# SN32F780 register map
Vendor: SONiX Technology Co., Ltd.; Series: SN32F780; File version: 0.75
CPU: CM0 r0p0, little endian, no MPU, no FPU, 2 interrupt priority bits
Registers are 32-bit, read-write, reset 0x0 unless marked. A register's access mark holds for its fields unless they carry their own. Offsets are from the block's base; [hi:lo] are bit positions; {n}, {i} and the like mark numbered series.

## SN_CT16B1 — 16-bit Timer 1 with Capture function
Base 0x40002000
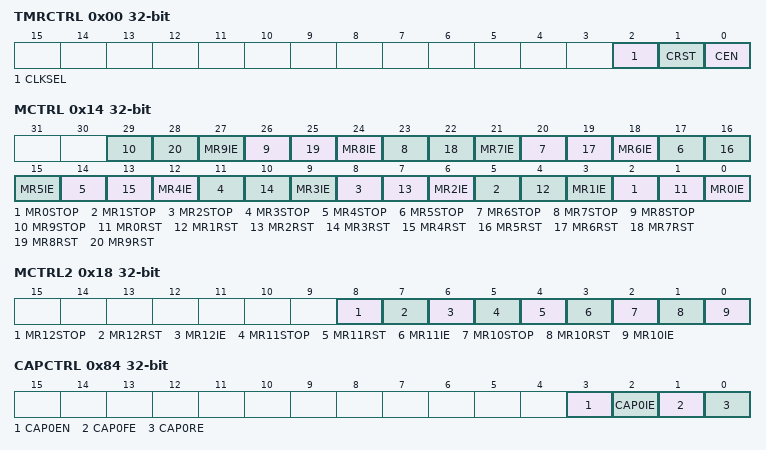
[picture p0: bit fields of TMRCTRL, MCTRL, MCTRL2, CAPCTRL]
0x00 TMRCTRL — Offset:0x00 CT16Bn Timer Control Register
  [2] CLKSEL — PCLK source
    0=HCLK (CT16Bn PCLK source=HCLK); 1=PLL_VCO (CT16Bn PCLK source=PLL_VCO)
  [1] CRST — Counter Reset
    0=Disable; 1=Reset Counter (Timer Counter and the Prescale Counter are synchronously reset on the next positive edge of PCLK)
  [0] CEN — Counter enable
    0=Disable counter; 1=Enable Timer Counter and Prescale Counter for counting
0x04 TC — Offset:0x04 CT16Bn Timer Counter Register
  [15:0] TC — Timer Counter
0x08 PRE — Offset:0x08 CT16Bn Prescale Register
  [7:0] PRE — Prescaler
0x0C PC — Offset:0x0C CT16Bn Prescale Counter Register
  [7:0] PC — Prescaler Counter
0x10 CNTCTRL — Offset:0x10 CT16Bn Counter Control Register
  [1:0] CTM — Counter/Timer Mode
    0=Timer Mode: every rising PCLK edge; 1=Counter Mode 1 (TC is incremented on rising edges on the CAP0 input selected by CIS bits.); 2=Counter Mode 2 (TC is incremented on falling edges on the CAP0 input selected by CIS bits.); 3=Counter Mode 3 (TC is incremented on both edges on the CAP0 input selected by CIS bits.)
0x14 MCTRL (reset mask 0x3FFFFFF) — Offset:0x14 CT16Bn Match Control Register
  [3n+2] MR{n}STOP (n=0..9) — Stop TC and PC and clear CEN bit when MR{n} matches TC
    0=Disable; 1=Enable (Stop TC and PC and clear CEN bit when MR{n} matches TC)
  [3n+1] MR{n}RST (n=0..9) — Enable reset TC when MR{n} matches TC
    0=Disable; 1=Enable (Reset TC when MR{n} matches TC)
  [3n] MR{n}IE (n=0..9) — Enable generating an interrupt when MR{n} matches TC
    0=Disable; 1=Enable (Generating an interrupt when MR{n} matches TC)
0x18 MCTRL2 — Offset:0x18 CT16Bn Match Control Register 2
  [8] MR12STOP — Stop TC and PC and clear CEN bit when MR12 matches TC
    0=Disable; 1=Enable (Stop TC and PC and clear CEN bit when MR12 matches TC)
  [7] MR12RST — Enable reset TC when MR12 matches TC
    0=Disable; 1=Enable (Reset TC when MR12 matches TC)
  [6] MR12IE — Enable generating an interrupt when MR12 matches TC
    0=Disable; 1=Enable (Generating an interrupt when MR12 matches TC)
  [5] MR11STOP — Stop TC and PC and clear CEN bit when MR11 matches TC
    0=Disable; 1=Enable (Stop TC and PC and clear CEN bit when MR11 matches TC)
  [4] MR11RST — Enable reset TC when MR11 matches TC
    0=Disable; 1=Enable (Reset TC when MR11 matches TC)
  [3] MR11IE — Enable generating an interrupt when MR11 matches TC
    0=Disable; 1=Enable (Generating an interrupt when MR11 matches TC)
  [2] MR10STOP — Stop TC and PC and clear CEN bit when MR10 matches TC
    0=Disable; 1=Enable (Stop TC and PC and clear CEN bit when MR10 matches TC)
  [1] MR10RST — Enable reset TC when MR10 matches TC
    0=Disable; 1=Enable (Reset TC when MR10 matches TC)
  [0] MR10IE — Enable generating an interrupt when MR10 matches TC
    0=Disable; 1=Enable (Generating an interrupt when MR10 matches TC)
{0x20+4i} MR{i} (reset mask 0xFFFF) (i=0..12) — Offset:{0x20+4i} CT16Bn MR{i} Register
0x84 CAPCTRL — Offset:0x84 CT16Bn Capture Control Register
  [3] CAP0EN — CAP0 function enable
    0=Disable; 1=Enable CAP0 function for external Capture pin
  [2] CAP0IE — Interrupt on CT16Bn_CAP0 event
    0=Disable; 1=Enable (A CAP0 load due to a CT16Bn_CAP0 event will generate an interrupt.)
  [1] CAP0FE — Capture/Reset on CT16Bn_CAP0 signal falling edge
    0=Disable; 1=Enable (A sequence of 1 then 0 on CT16Bn_CAP0 will cause CAP0 to be loaded with the contents of TC.)
  [0] CAP0RE — Capture/Reset on CT16Bn_CAP0 signal rising edge
    0=Disable; 1=Enable (A sequence of 0 then 1 on CT16Bn_CAP0 will cause CAP0 to be loaded with the contents of TC.)
0x88 CAP0 ro — Offset:0x88 CT16Bn CAP0 Register
  [15:0] CAP0 — Timer counter capture value
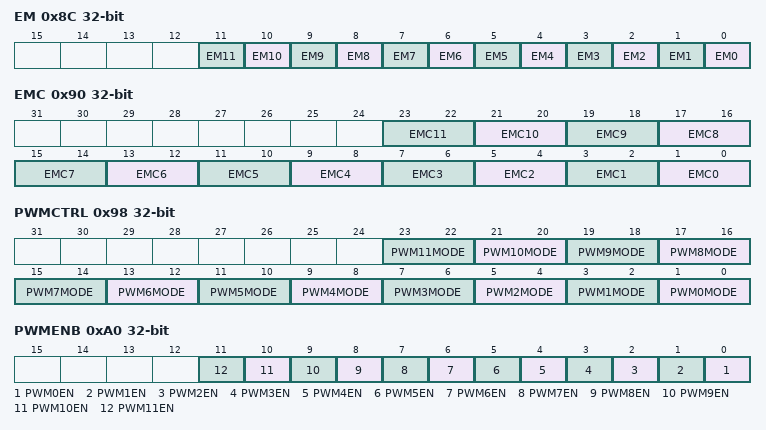
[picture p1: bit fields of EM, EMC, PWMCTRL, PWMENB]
0x8C EM — Offset:0x8C CT16Bn External Match Register
  [n] EM{n} (n=8..11) — When the TC matches MR{n}, this bit will act according to EMC{n}[1:0], and also drive the state of CT16Bn_PWM{n-8} output.
  [n] EM{n} (n=4..7) — When the TC matches MR{n}, this bit will act according to EMC{n}[1:0], and also drive the state of CT16Bn_PWM{n-4} output.
  [n] EM{n} (n=0..3) — When the TC matches MR{n}, this bit will act according to EMC{n}[1:0], and also drive the state of CT16Bn_PWM{n} output.
0x90 EMC — Offset:0x90 CT16Bn External Match Control register
  [2n+1:2n] EMC{n} (n=0..11) — CT16Bn_PWM{n} functionality
    0=Do Nothing; 1=Low (CT16Bn_PWM{n} pin is LOW); 2=High (CT16Bn_PWM{n} pin is HIGH); 3=Toggle CT16Bn_PWM{n} pin
0x98 PWMCTRL — Offset:0x98 CT16Bn PWM Control Register
  [2n+1:2n] PWM{n}MODE (n=0..11) — PWM{n} output mode
    0=PWM mode 1 (During up-counting, PWM{n} is 0 when TC is less than MR{n}. During down-counting, PWM{n} is 1 when TC is larger/equal than MR{n}); 1=PWM mode 2 (During up-counting, PWM{n} is 1 when TC is less than MR{n}. During down-counting, PWM{n} is 0 when TC is larger/equal than MR{n}); 2=Force 0 (PWM{n} is forced to 0); 3=Force 1 (PWM{n} is forced to 1)
0xA0 PWMENB — Offset:0xA0 CT16Bn PWM Enable register
  [n] PWM{n}EN (n=0..11) — PWM{n} enable
    0=Disable (CT16Bn_PWM{n} is controlled by EM{n}); 1=Enable PWM mode for CT16Bn_PWM{n}
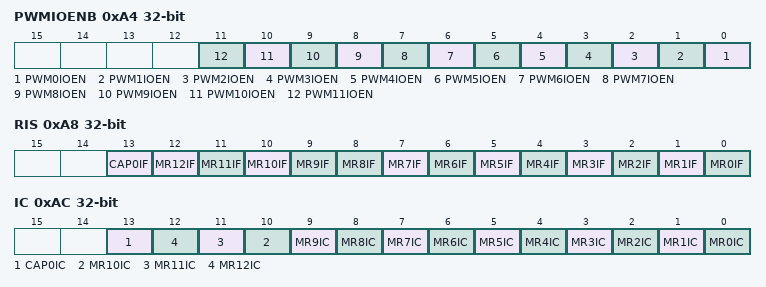
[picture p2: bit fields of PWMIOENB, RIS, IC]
0xA4 PWMIOENB — Offset:0xA4 CT16Bn PWM IO Enable register
  [n] PWM{n}IOEN (n=0..11) — CT16Bn_PWM{n}/GPIO selection
    0=Disable (CT16Bn_PWM{n} pin is act as GPIO); 1=Enable (CT16Bn_PWM{n} pin act as match output, and output depends on PWM{n}EN bit)
0xA8 RIS ro — Offset:0xA8 CT16Bn Raw Interrupt Status Register
  [13] CAP0IF — Capture channel 0 interrupt flag
    0=No (No interrupt on CAP0); 1=Met interrupt requirements (Interrupt requirements met on CAP0)
  [n] MR{n}IF (n=9..12) — Match channel {n} interrupt flag
    0=No (No interrupt on match channel {n}); 1=Met interrupt requirements (Interrupt requirements met on match channel {n})
  [8] MR8IF — Match channel 8 interrupt flag
    0=No interrupt on match channel 8; 1=Met interrupt requirements (Interrupt requirements met on match channel 8)
  [7] MR7IF — Match channel 7 interrupt flag
    0=No (No interrupt on match channel 7); 1=Met interrupt requirements (Interrupt requirements met on match channel 7)
  [6] MR6IF — Match channel 6 interrupt flag
    0=No (No interrupt on match channel 6); 1=Met interrupt requirements (Interrupt requirements met on match channel 6)
  [5] MR5IF — Match channel 5 interrupt flag
    0=No (No interrupt on match channel 5); 1=Met interrupt requirements (Interrupt requirements met on match channel 5)
  [4] MR4IF — Match channel 4 interrupt flag
    0=No interrupt on match channel 4; 1=Met interrupt requirements (Interrupt requirements met on match channel 4)
  [3] MR3IF — Match channel 3 interrupt flag
    0=No (No interrupt on match channel 3); 1=Met interrupt requirements (Interrupt requirements met on match channel 3)
  [2] MR2IF — Match channel 2 interrupt flag
    0=No (No interrupt on match channel 2); 1=Met interrupt requirements (Interrupt requirements met on match channel 2)
  [1] MR1IF — Match channel 1 interrupt flag
    0=No (No interrupt on match channel 1); 1=Met interrupt requirements (Interrupt requirements met on match channel 1)
  [0] MR0IF — Match channel 0 interrupt flag
    0=No interrupt on match channel 0; 1=Met interrupt requirements (Interrupt requirements met on match channel 0)
0xAC IC wo — Offset:0xAC CT16Bn Interrupt Clear Register
  [13] CAP0IC — CAP0IF clear bit
    0=No effect; 1=Clear CAP0IF
  [n] MR{n}IC (n=0..12) — MR{n}IF clear bit
    0=No effect; 1=Clear MR{n}IF
